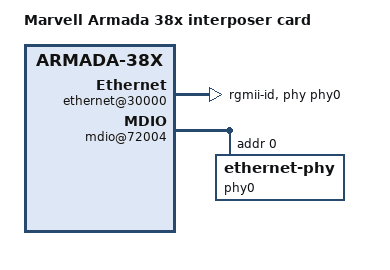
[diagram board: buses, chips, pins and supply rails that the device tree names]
/*
 * Device Tree file for Marvell INTERPOSER card
 * 88F6811, 88F6821 interposer card
 * Applicable for:
 *    * AC3X RD board
 *
 * Copyright (C) 2017 Marvell
 *
 * This file is dual-licensed: you can use it either under the terms
 * of the GPL or the X11 license, at your option. Note that this dual
 * licensing only applies to this file, and not this project as a
 * whole.
 *
 *  a) This file is licensed under the terms of the GNU General Public
 *     License version 2.  This program is licensed "as is" without
 *     any warranty of any kind, whether express or implied.
 *
 * Or, alternatively,
 *
 *  b) Permission is hereby granted, free of charge, to any person
 *     obtaining a copy of this software and associated documentation
 *     files (the "Software"), to deal in the Software without
 *     restriction, including without limitation the rights to use,
 *     copy, modify, merge, publish, distribute, sublicense, and/or
 *     sell copies of the Software, and to permit persons to whom the
 *     Software is furnished to do so, subject to the following
 *     conditions:
 *
 *     The above copyright notice and this permission notice shall be
 *     included in all copies or substantial portions of the Software.
 *
 *     THE SOFTWARE IS PROVIDED "AS IS", WITHOUT WARRANTY OF ANY KIND,
 *     EXPRESS OR IMPLIED, INCLUDING BUT NOT LIMITED TO THE WARRANTIES
 *     OF MERCHANTABILITY, FITNESS FOR A PARTICULAR PURPOSE AND
 *     NONINFRINGEMENT. IN NO EVENT SHALL THE AUTHORS OR COPYRIGHT
 *     HOLDERS BE LIABLE FOR ANY CLAIM, DAMAGES OR OTHER LIABILITY,
 *     WHETHER IN AN ACTION OF CONTRACT, TORT OR OTHERWISE, ARISING
 *     FROM, OUT OF OR IN CONNECTION WITH THE SOFTWARE OR THE USE OR
 *     OTHER DEALINGS IN THE SOFTWARE.
 */
#include "armada-385-amc.dts"

/ {
	model = "Marvell Armada 38x interposer card";

	soc {
		internal-regs {
			flash@d0000 {
				nand-ecc-strength = <4>;
			};

			ethernet@70000 {
				status = "disable";
			};
			ethernet@30000 {
				pinctrl-names = "default";
				/*
				 * The Reference Clock 0 is used to provide a
				 * clock to the PHY
				 */
				pinctrl-0 = <&ge0_rgmii_pins>, <&ref_clk0_pins>;
				status = "okay";
				phy = <&phy0>;
				phy-mode = "rgmii-id";
			};
			mdio@72004 {
				phy0: ethernet-phy@1 {
					reg = <0>;
				};
			};
		};
	};
};
